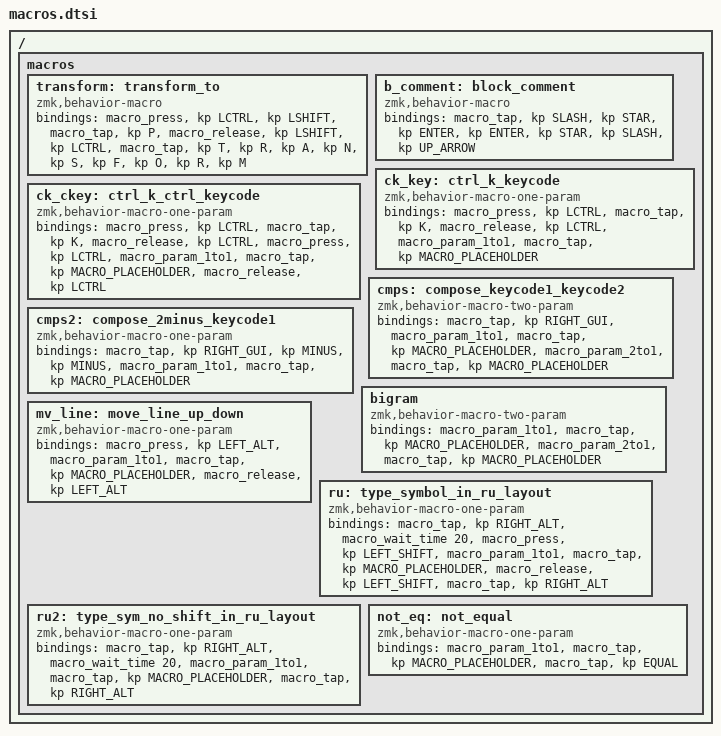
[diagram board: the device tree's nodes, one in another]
/* macros.dtsi */

/ {
    macros {
      transform: transform_to {
        compatible = "zmk,behavior-macro";
        #binding-cells = <0>;
        bindings =
          <&macro_press &kp LCTRL &kp LSHIFT>,
          <&macro_tap &kp P>,
          <&macro_release &kp LSHIFT &kp LCTRL>,
          <&macro_tap &kp T &kp R &kp A &kp N &kp S &kp F &kp O &kp R &kp M>;
      };

      b_comment: block_comment {
        compatible = "zmk,behavior-macro";
        #binding-cells = <0>;
        bindings =
          <&macro_tap &kp SLASH &kp STAR &kp ENTER &kp ENTER &kp STAR &kp SLASH &kp UP_ARROW>;
      };

      ck_key: ctrl_k_keycode {
        compatible = "zmk,behavior-macro-one-param";
        #binding-cells = <1>;
        bindings =
          <&macro_press &kp LCTRL>,
          <&macro_tap &kp K>,
          <&macro_release &kp LCTRL>,
          <&macro_param_1to1>,
          <&macro_tap &kp MACRO_PLACEHOLDER>;
      };

      ck_ckey: ctrl_k_ctrl_keycode {
        compatible = "zmk,behavior-macro-one-param";
        #binding-cells = <1>;
        bindings =
          <&macro_press &kp LCTRL>,
          <&macro_tap &kp K>,
          <&macro_release &kp LCTRL>,
          <&macro_press &kp LCTRL>,
          <&macro_param_1to1>,
          <&macro_tap &kp MACRO_PLACEHOLDER>,
          <&macro_release &kp LCTRL>;
      };

      cmps: compose_keycode1_keycode2 {
        compatible = "zmk,behavior-macro-two-param";
        #binding-cells = <2>;
        bindings =
          <&macro_tap &kp RIGHT_GUI>,
          <&macro_param_1to1>,
          <&macro_tap &kp MACRO_PLACEHOLDER>,
          <&macro_param_2to1>,
          <&macro_tap &kp MACRO_PLACEHOLDER>;
      };

      cmps2: compose_2minus_keycode1 {
        compatible = "zmk,behavior-macro-one-param";
        #binding-cells = <1>;
        bindings =
          <&macro_tap &kp RIGHT_GUI &kp MINUS &kp MINUS>,
          <&macro_param_1to1>,
          <&macro_tap &kp MACRO_PLACEHOLDER>;
      };

      bigram: bigram {
        compatible = "zmk,behavior-macro-two-param";
        #binding-cells = <2>;
        bindings =
          <&macro_param_1to1>,
          <&macro_tap &kp MACRO_PLACEHOLDER>,
          <&macro_param_2to1>,
          <&macro_tap &kp MACRO_PLACEHOLDER>;
      };

      mv_line: move_line_up_down {
        compatible = "zmk,behavior-macro-one-param";
        #binding-cells = <1>;
        bindings =
          <&macro_press &kp LEFT_ALT>,
          <&macro_param_1to1>,
          <&macro_tap &kp MACRO_PLACEHOLDER>,
          <&macro_release &kp LEFT_ALT>;
      };

      ru: type_symbol_in_ru_layout {
        compatible = "zmk,behavior-macro-one-param";
        #binding-cells = <1>;
        bindings =
          <&macro_tap &kp RIGHT_ALT>,
          <&macro_wait_time 20>,
          <&macro_press &kp LEFT_SHIFT>,
          <&macro_param_1to1>,
          <&macro_tap &kp MACRO_PLACEHOLDER>,
          <&macro_release &kp LEFT_SHIFT>,
          <&macro_tap &kp RIGHT_ALT>;
      };

      ru2: type_sym_no_shift_in_ru_layout {
        compatible = "zmk,behavior-macro-one-param";
        #binding-cells = <1>;
        bindings =
          <&macro_tap &kp RIGHT_ALT>,
          <&macro_wait_time 20>,
          <&macro_param_1to1>,
          <&macro_tap &kp MACRO_PLACEHOLDER>,
          <&macro_tap &kp RIGHT_ALT>;
      };

      not_eq: not_equal {
        compatible = "zmk,behavior-macro-one-param";
        #binding-cells = <1>;
        bindings =
          <&macro_param_1to1>,
          <&macro_tap &kp MACRO_PLACEHOLDER>,
          <&macro_tap &kp EQUAL>;
      };

  };
};
